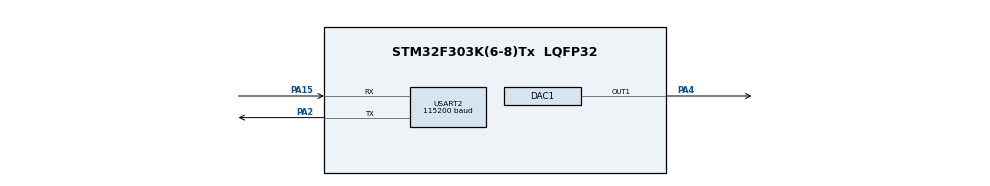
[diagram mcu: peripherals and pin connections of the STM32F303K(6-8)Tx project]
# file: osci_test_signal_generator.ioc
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Mcu.Family=STM32F3
Mcu.Name=STM32F303K(6-8)Tx
Mcu.Package=LQFP32
NVIC.PriorityGroup=NVIC_PRIORITYGROUP_4
NVIC.TIM1_UP_TIM16_IRQn=true\:0\:0\:false\:false\:true\:true\:true
NVIC.USART2_IRQn=true\:0\:0\:false\:false\:true\:true\:true
PA15.Mode=Asynchronous
PA15.Signal=USART2_RX
PA2.Mode=Asynchronous
PA2.Signal=USART2_TX
PA4.Signal=COMP_DAC11_group
ProjectManager.HeapSize=0x200
ProjectManager.StackSize=0x400
ProjectManager.TargetToolchain=STM32CubeIDE
RCC.AHBFreq_Value=8000000
RCC.APB1Freq_Value=8000000
RCC.APB1TimFreq_Value=8000000
RCC.APB2Freq_Value=8000000
RCC.APB2TimFreq_Value=8000000
RCC.CortexFreq_Value=8000000
RCC.HCLKFreq_Value=8000000
RCC.HSE_VALUE=8000000
RCC.HSI_VALUE=8000000
RCC.SYSCLKFreq_VALUE=8000000
SH.COMP_DAC11_group.0=DAC1_OUT1,DAC_OUT1
USART2.BaudRate=115200
USART2.VirtualMode-Asynchronous=VM_ASYNC
VP_TIM1_VS_ClockSourceINT.Mode=Internal
board=custom

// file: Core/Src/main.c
/* USER CODE BEGIN Header */
/**
  ******************************************************************************
  * @file           : main.c
  * @brief          : Main program body
  ******************************************************************************
  * @attention
  *
  * <h2><center>&copy; Copyright (c) 2019 STMicroelectronics.
  * All rights reserved.</center></h2>
  *
  * This software component is licensed by ST under BSD 3-Clause license,
  * the "License"; You may not use this file except in compliance with the
  * License. You may obtain a copy of the License at:
  *                        opensource.org/licenses/BSD-3-Clause
  *
  ******************************************************************************
  */
/* USER CODE END Header */

#include "main.h"
#include "dac.h"
#include "tim.h"
#include "usart.h"
#include "gpio.h"
#include "cppmain.h"

/* USER CODE BEGIN PV */
void * adj_IT_reference;
/* USER CODE END PV */

void SystemClock_Config(void);
/* USER CODE BEGIN PFP */
void (*tim1_callback) (void*);
void (*usart2_rxne_callback) (void*);
/* USER CODE END PFP */

int main(void)
{

  /* MCU Configuration--------------------------------------------------------*/

  /* Reset of all peripherals, Initializes the Flash interface and the Systick. */

  LL_APB2_GRP1_EnableClock(LL_APB2_GRP1_PERIPH_SYSCFG);
  LL_APB1_GRP1_EnableClock(LL_APB1_GRP1_PERIPH_PWR);

  NVIC_SetPriorityGrouping(NVIC_PRIORITYGROUP_4);

  /* System interrupt init*/

  /* Configure the system clock */
  SystemClock_Config();

  /* Initialize all configured peripherals */
  MX_GPIO_Init();
  MX_DAC1_Init();
  MX_TIM1_Init();
  MX_USART2_UART_Init();

  /* Infinite loop */
  while (1)
  {

    /* USER CODE BEGIN 3 */
	  cppmain();
  }
  /* USER CODE END 3 */
}

void SystemClock_Config(void)
{
  LL_FLASH_SetLatency(LL_FLASH_LATENCY_0);

  if(LL_FLASH_GetLatency() != LL_FLASH_LATENCY_0)
  {
  Error_Handler();
  }
  LL_RCC_HSI_Enable();

   /* Wait till HSI is ready */
  while(LL_RCC_HSI_IsReady() != 1)
  {

  }
  LL_RCC_HSI_SetCalibTrimming(16);
  LL_RCC_SetAHBPrescaler(LL_RCC_SYSCLK_DIV_1);
  LL_RCC_SetAPB1Prescaler(LL_RCC_APB1_DIV_1);
  LL_RCC_SetAPB2Prescaler(LL_RCC_APB1_DIV_1);
  LL_RCC_SetSysClkSource(LL_RCC_SYS_CLKSOURCE_HSI);

   /* Wait till System clock is ready */
  while(LL_RCC_GetSysClkSource() != LL_RCC_SYS_CLKSOURCE_STATUS_HSI)
  {

  }
  LL_Init1msTick(8000000);
  LL_SYSTICK_SetClkSource(LL_SYSTICK_CLKSOURCE_HCLK);
  LL_SetSystemCoreClock(8000000);
  LL_RCC_SetTIMClockSource(LL_RCC_TIM1_CLKSOURCE_PCLK2);
}

void Error_Handler(void)
{
}

/************************ (C) COPYRIGHT STMicroelectronics *****END OF FILE****/
